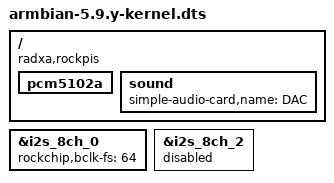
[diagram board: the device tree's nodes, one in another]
// Definitions for DAC
/dts-v1/;
/plugin/;

/ {
        compatible = "radxa,rockpis", "rockchip,rk3308";

        fragment@0 {
                target = <&i2s_8ch_0>;
                __overlay__ {
                        #sound-dai-cells = <0>;
                        rockchip,bclk-fs = <64>;
                        status = "okay";
                        };
                };

        fragment@1 {
                target = <&i2s_8ch_2>;
                __overlay__ {
                        #sound-dai-cells = <0>;
                        status = "disabled";
                        };
                };

        fragment@2 {
                target-path = "/";
                __overlay__ {
                        pcm5102a {
                                status = "okay";
                                };
                        sound {
                                simple-audio-card,name = "DAC";
                                status = "okay";
                                };
                        };
                };
       };
